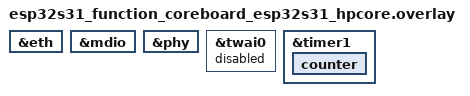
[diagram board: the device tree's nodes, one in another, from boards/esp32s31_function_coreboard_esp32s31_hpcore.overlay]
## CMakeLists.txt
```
# SPDX-License-Identifier: GPL-3.0-or-later

cmake_minimum_required(VERSION 3.20.0)

find_package(Zephyr REQUIRED HINTS $ENV{ZEPHYR_BASE})
project(esp_sdr_txstream_eth)

include(${CMAKE_CURRENT_LIST_DIR}/../../lib/esp_sdr/place.cmake)

set(txs_dir ${CMAKE_CURRENT_LIST_DIR}/../../lib/esp_sdr/src/txs)
# The cookie protocol of the control port and the header templates are stream_eth's, compiled from there.
set(eth_dir ${CMAKE_CURRENT_LIST_DIR}/../stream_eth/src)
target_sources(app PRIVATE src/main.c src/tx_boot.c src/tx_shell.c src/tx_stream.c src/tx_tone.c
  src/tx_net.c src/tx_sess.c ${eth_dir}/ctlproto.c ${eth_dir}/netframe.c
  ${txs_dir}/txs_flip.c ${txs_dir}/txs_jit.c ${txs_dir}/txs_credit.c
  ${txs_dir}/txs_wire.c ${txs_dir}/txs_expand.c)
target_sources_ifdef(CONFIG_APP_TXS_INJECT app PRIVATE src/tx_inject.c)
target_include_directories(app PRIVATE ${txs_dir} ${eth_dir})

# The PIE kernel: preprocessed by Zephyr's compiler (the placement macros), assembled by Espressif's
# assembler (xespv2p2), the rest by Zephyr's.
if(CONFIG_ESP_SDR_TXS_PIE)
  find_program(ESP_AS riscv32-esp-elf-as)
  if(NOT ESP_AS)
    message(FATAL_ERROR "CONFIG_ESP_SDR_TXS_PIE needs riscv32-esp-elf-as (the dev shell has it)")
  endif()
  set(pie_s ${CMAKE_CURRENT_BINARY_DIR}/txs_pie.s)
  set(pie_o ${CMAKE_CURRENT_BINARY_DIR}/txs_pie.o)
  add_custom_command(OUTPUT ${pie_o}
    COMMAND ${CMAKE_C_COMPILER} -E -P -x assembler-with-cpp -imacros ${AUTOCONF_H}
            -I${ZEPHYR_BINARY_DIR}/include/generated -I${CMAKE_CURRENT_LIST_DIR}/../../include
            -o ${pie_s} ${txs_dir}/txs_pie.S
    COMMAND ${ESP_AS} -march=rv32imafc_zicsr_zifencei_xespv2p2 -mabi=ilp32f -o ${pie_o} ${pie_s}
    DEPENDS ${txs_dir}/txs_pie.S ${ZEPHYR_BINARY_DIR}/include/generated/esp_sdr_place_rules.h
    VERBATIM)
  target_sources(app PRIVATE ${pie_o} ${txs_dir}/txs_pie.c)
  set_source_files_properties(${pie_o} PROPERTIES EXTERNAL_OBJECT TRUE GENERATED TRUE)
endif()
target_include_directories(app PRIVATE ${CMAKE_CURRENT_LIST_DIR}/../../include)

# net_buf_unref() and what it calls run on CPU 1, per packet: IRAM, not the flash cache
zephyr_linker_sources(RAMFUNC_SECTION ${CMAKE_CURRENT_LIST_DIR}/ram_netbuf.ld)

# The layout of the transmit image is checked after every link: PSRAM only where it is safe (a store fault at
# boot, or CPU 1 and the interrupts reaching it, otherwise), the rest of scripts/tcm_groups.py --tx. A failure
# fails the build.
if(CONFIG_ESP_SDR_S31_TXMEM)
  add_custom_target(txs_layout_check ALL
    COMMAND ${CMAKE_COMMAND} -E env READELF=${CMAKE_READELF} ${PYTHON_EXECUTABLE}
            ${CMAKE_CURRENT_LIST_DIR}/../../scripts/tcm_groups.py
            ${ZEPHYR_BINARY_DIR}/${CONFIG_KERNEL_BIN_NAME}.elf --tx
    VERBATIM)
  add_dependencies(txs_layout_check ${logical_target_for_zephyr_elf})
endif()
target_compile_options(app PRIVATE -O2)
```

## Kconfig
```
# SPDX-License-Identifier: GPL-3.0-or-later

mainmenu "ESP-SDR transmit stream over Ethernet"

config APP_TXS_INJECT
	bool "The injector: sample packets made on the board (tx tone, tx inject)"
	help
	  A thread on CPU 0 that makes the packets the sender would, for tests without a host. It costs
	  about 2.4 KB of group 3 (its stack, thread and ring) and a few hundred bytes of group 0, which
	  the network side leaves no room for: injector.conf builds it with two receive buffers less. With
	  it off (the default), the network is the only source and `tx tone` and `tx inject` answer "not
	  supported".

source "Kconfig.zephyr"
```

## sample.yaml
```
sample:
  name: ESP-SDR transmit stream over Ethernet
  description: >-
    The S31 DAC streamed by whole-group ownership flips on CPU 1, fed over UDP (control 4992, samples
    4994; vrt_tx), in the transmit memory layout, with the gigabit Ethernet up
common:
  tags: esp-sdr
  platform_allow:
    - esp32s31_function_coreboard/esp32s31/hpcore
  integration_platforms:
    - esp32s31_function_coreboard/esp32s31/hpcore
tests:
  sample.esp_sdr.txstream_eth:
    build_only: true
  sample.esp_sdr.txstream_eth.injector:
    build_only: true
    extra_args: EXTRA_CONF_FILE=injector.conf
```

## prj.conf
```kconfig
# The transmit stream: the DAC by two-group flips, a tone from the injector, Ethernet up.
# Memory layout and network buffers as apps/rxbench/txmem.conf.
CONFIG_ESP_SDR=y
CONFIG_ESP_SDR_PHY_ONLY=y
CONFIG_ESP_SDR_REPLAY=y
CONFIG_ESP_SDR_RX_DECIM=n
CONFIG_ESP_SDR_S31_TXMEM=y
CONFIG_ESP_SDR_TXS_PIE=y

CONFIG_LOG=y
CONFIG_LOG_MODE_DEFERRED=y
# 512 B: the buffer is in group 0 (BSS), where the IPI and per-CPU run queue code of PIN_ONLY and the PSRAM driver's
# code took the room
CONFIG_LOG_BUFFER_SIZE=512
# The main thread is the stream's control thread: chain on and off (PHY), the report
CONFIG_MAIN_STACK_SIZE=3072
CONFIG_PRINTK=y
CONFIG_SHELL=y
CONFIG_SHELL_STACK_SIZE=4096
# The injector runs at the lowest priority: the shell is one above it
CONFIG_SHELL_THREAD_PRIORITY_OVERRIDE=y
CONFIG_SHELL_THREAD_PRIORITY=13
# A stack overflow is caught at the next context switch (a word per thread)
CONFIG_STACK_SENTINEL=y
CONFIG_KERNEL_SHELL=y
CONFIG_THREAD_NAME=y
CONFIG_FPU_SHARING=y

# The deadman's timer
CONFIG_COUNTER=y

# PSRAM (16 MB octal on the CoreBoard) at 250 MHz, the MPLL at 500 MHz (esp_psram_impl_ap_oct.c sets the PLL for
# this speed; at 400 MHz, SPIRAM_SPEED_200M, the PLL-derived clocks would change). The stacks of the threads with
# slack and cold data go there, the rest stays in internal RAM: lib/esp_sdr/esp_sdr_txmem_s31.ld, place.h, README.
# main() logs the PLL-derived clocks once (tx_boot.c). CPU 1 never touches PSRAM.
CONFIG_ESP_SPIRAM=y
CONFIG_SPIRAM_MODE_OCT=y
CONFIG_SPIRAM_SPEED_250M=y

# Ethernet: YT8531 on RGMII, the fork's DWC MAC, gigabit.
CONFIG_NETWORKING=y
CONFIG_NET_L2_ETHERNET=y
CONFIG_ETH_DRIVER=y
CONFIG_ETHERNET_LOG_LEVEL_WRN=y
CONFIG_PHY_LOG_LEVEL_WRN=y
CONFIG_MDIO_LOG_LEVEL_WRN=y
CONFIG_MDIO=y
CONFIG_ETH_DWMAC_RX_FAST=y
CONFIG_ETH_DWMAC_TX_RAMFUNC=y
# the status and the replies go out as prepared frames (dwmac_send_frames), not through the stack
CONFIG_ETH_DWMAC_TX_FAST=y
CONFIG_NET_BUF_DATA_SIZE=1536
CONFIG_NET_BUF_ALIGNMENT=64
# 43 receive buffers of 1664 B in group 3: 16 with the MAC, TX_HOLD = 25 (src/tx_hold.h) for the stream, 2 for the
# stack (tx_stream.c checks). The stacks of the threads with slack in PSRAM (above) freed the room (9 buffers, 224 B
# left in group 3: the linker stops the build when a buffer more does not fit).
CONFIG_DWMAC_NB_RX_DESCS=16
CONFIG_NET_BUF_RX_COUNT=43
CONFIG_NET_PKT_RX_COUNT=16
CONFIG_NET_BUF_TX_COUNT=4
CONFIG_NET_PKT_TX_COUNT=4
CONFIG_DWMAC_NB_TX_DESCS=16

# DHCPv4, IPv6 link-local and autoconfiguration; answers ping and neighbour requests.
CONFIG_NET_IPV4=y
CONFIG_NET_IPV6=y
CONFIG_NET_UDP=y
CONFIG_NET_DHCPV4=y
CONFIG_NET_DHCPV4_INITIAL_DELAY_MAX=2
CONFIG_NET_IPV6_ND=y
CONFIG_NET_IF_UNICAST_IPV6_ADDR_COUNT=5
CONFIG_NET_IF_IPV6_PREFIX_COUNT=3
# The tables of the stack, sized for one host, one router and the DHCP server (group 0 has no room to spare: the PSRAM
# driver's code and data are in it)
CONFIG_NET_MAX_ROUTES=2
CONFIG_NET_IPV4_MAX_ROUTES=2
CONFIG_NET_IPV6_MAX_NEIGHBORS=4
CONFIG_NET_IPV4_MAX_NEIGHBORS=2
CONFIG_NET_MAX_CONN=5
CONFIG_NET_MAX_CONTEXTS=5
CONFIG_NET_CONFIG_SETTINGS=y
CONFIG_NET_CONFIG_NEED_IPV4=y
CONFIG_NET_CONFIG_NEED_IPV6=y
CONFIG_NET_CONFIG_MY_IPV4_ADDR=""
CONFIG_NET_CONFIG_PEER_IPV4_ADDR=""
CONFIG_NET_CONFIG_INIT_TIMEOUT=10
CONFIG_NET_SHELL=y
CONFIG_NET_STATISTICS=y
CONFIG_NET_STATISTICS_ETHERNET=y
CONFIG_NET_STATISTICS_ETHERNET_VENDOR=y

CONFIG_SYSTEM_WORKQUEUE_PRIORITY=7
CONFIG_NET_TC_THREAD_PREEMPTIVE=y
CONFIG_NET_TC_THREAD_PRIO_CUSTOM=y
CONFIG_NET_TC_TX_THREAD_BASE_PRIO=8
CONFIG_NET_TC_RX_THREAD_BASE_PRIO=8
CONFIG_NET_MGMT_EVENT_STACK_SIZE=3072
CONFIG_NET_RX_STACK_SIZE=4096
CONFIG_NET_TX_STACK_SIZE=4096
CONFIG_HEAP_MEM_POOL_SIZE=8192

# The network and every device interrupt on CPU 0, the stream's flips alone on CPU 1.
CONFIG_SMP=y
CONFIG_MP_MAX_NUM_CPUS=2
CONFIG_SCHED_CPU_MASK=y
# Every thread starts on CPU 0 alone (the network, the shell, the log, the status and control threads, main); the
# flip thread is pinned to CPU 1 before it starts (tx_stream.c). A wakeup then never sends CPU 1 a scheduler
# interrupt: with IPI_OPTIMIZE only the CPUs a thread may run on, and where it would preempt, are interrupted.
CONFIG_SCHED_CPU_MASK_PIN_ONLY=y
CONFIG_IPI_OPTIMIZE=y

# The status thread sleeps a tick at a time (src/tx_net.c): 100 us
CONFIG_SYS_CLOCK_TICKS_PER_SEC=10000
```

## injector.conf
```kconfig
# SPDX-License-Identifier: GPL-3.0-or-later
# The injector (tx tone, tx inject: sample packets made on the board, no host needed) next to the network
# side. Its 2.4 KB do not fit group 3 with the 43 receive buffers: two fewer (3.3 KB) make room. The
# injector holds TX_BUFFERS = 21 of the 41 and the MAC 16, which leaves 4 for the stack: for a bench without a
# host, not for the network run (op_start refuses a run from the network in this build).
#   west build ... -- -DEXTRA_CONF_FILE=injector.conf
CONFIG_APP_TXS_INJECT=y
CONFIG_NET_BUF_RX_COUNT=41
```

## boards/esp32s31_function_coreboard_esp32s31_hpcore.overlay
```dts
/*
 * SPDX-License-Identifier: GPL-3.0-or-later
 *
 * The gigabit Ethernet of the ESP32-S31-Function-CoreBoard-1: YT8531 on RGMII (GPIO4-19, MDC 5,
 * MDIO 6, PHY reset 7). TWAI shares GPIO13/14 with TX_CLK and RX_CLK. The diag16 pads (20-25,
 * 36-40, 42-44, 47, 48) are none of those.
 */

&eth {
	status = "okay";
};

&mdio {
	status = "okay";
};

&phy {
	status = "okay";
	/* Gigabit: the 125 MHz reference clock, so let the PHY offer 1000BASE-T. */
	/delete-property/ default-speeds;
};

&twai0 {
	status = "disabled";
};

/* The deadman of the DAC stream (src/tx_stream.c): a general purpose timer, interrupt on CPU 0. */
&timer1 {
	status = "okay";

	counter {
		status = "okay";
	};
};
```

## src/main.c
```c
/*
 * SPDX-License-Identifier: GPL-3.0-or-later
 *
 * The transmit stream's app: the shell commands "tx ..." in tx_shell.c, the network side in
 * tx_net.c (control on UDP 4992, samples through a hook on the MAC's receive path from UDP 4994), the
 * stream itself in tx_stream.c, the network as in apps/rxbench.
 */

#include <zephyr/app_version.h>
#include <zephyr/kernel.h>
#include <zephyr/drivers/ethernet/eth_dwmac_fast.h>
#include <zephyr/logging/log.h>
#include <zephyr/net/ethernet.h>
#include <zephyr/net/net_if.h>

#include "tx_boot.h"
#include "tx_net.h"
#include "tx_shell.h"
#include "tx_stream.h"

LOG_MODULE_REGISTER(txstream, LOG_LEVEL_INF);

int main(void)
{
	struct net_if *iface = net_if_get_first_by_type(&NET_L2_GET_NAME(ETHERNET));
	const struct device *eth;
	int ret;

	LOG_INF("txstream_eth %s", APP_VERSION_STRING);
	tx_mem_report();
	if (iface == NULL) {
		LOG_ERR("no Ethernet interface");
		tx_stream_ctl_run();
	}
	eth = net_if_get_device(iface);
	ret = tx_net_init(eth, iface);
	if (ret != 0) {
		LOG_ERR("network: %d", ret);
	}
	tx_shell_init(eth, iface);
	LOG_INF("\"tx boot\", then \"tx init\", then vrt_tx from the host (RF only after \"tx arm <minutes>\" with a subscriber)");
	/* this thread ends and starts the runs' chain and report (tx_stream.c) */
	tx_stream_ctl_run();
}
```

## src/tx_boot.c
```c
/*
 * SPDX-License-Identifier: GPL-3.0-or-later
 *
 * "tx boot": where the image, the heaps and the stacks ended up (the checks of scripts/tcm_groups.py
 * --tx, at run time), and the canary of the memory the DAC banks and the engine must not touch.
 */

#include <stdlib.h>
#include <string.h>

#include <zephyr/init.h>
#include <zephyr/kernel.h>
#include <zephyr/kernel_structs.h>
#include <zephyr/logging/log.h>
#include <soc/hp_system_reg.h>
#if defined(CONFIG_ESP_SPIRAM)
#include <esp_clk_tree.h>
#include <esp_psram.h>
#endif

#include <esp_sdr/esp_sdr.h>

#include "tx_boot.h"
#include "tx_stream.h"

LOG_MODULE_DECLARE(txstream, LOG_LEVEL_INF);

extern char _end[];
extern char _heap_sentry[];
extern char __esp_sdr_grp3_start[];
extern char __esp_sdr_grp3_end[];
#if defined(CONFIG_ESP_SDR_S31_TXMEM_PSRAM)
extern char __esp_sdr_psram_start[];
extern char __esp_sdr_psram_end[];
#endif
bool esp_sdr_s31_dump_ready(void);

#define GRP3_ORG 0x2F060000UL
#define GRP3_MAX 0x2F07AFB0UL
#define PSRAM_BASE 0x50000000UL
#define PSRAM_END  0x58000000UL
#define LPRAM_BASE 0x2E000000UL
#define LPRAM_END  0x2E008000UL
#define MAX_SHOWN 4U
#define MAX_THREADS 24U

static uint32_t seed;
static bool filled, with_stk;

static bool in_psram(uintptr_t a)
{
	return a >= PSRAM_BASE && a < PSRAM_END;
}

/* "group N", "psram" or "lp ram": where an address lies, for the reports */
static const char *where(uintptr_t a, char *buf, size_t n)
{
	if (in_psram(a)) {
		return "psram";
	}
	if (a >= LPRAM_BASE && a < LPRAM_END) {
		return "lp ram";
	}
	snprintk(buf, n, "group %u", GROUP_OF(a));
	return buf;
}

/* ---- PSRAM and the PLL-derived clocks ---- */

#if defined(CONFIG_ESP_SPIRAM)
/* The PSRAM's own init is a SYS_INIT at PRE_KERNEL_1 / CONFIG_KERNEL_INIT_PRIORITY_DEFAULT (soc/espressif/common/
 * esp_psram.c), the MSPI timing tuning and the chip's init included. These two bracket it by the CPU's cycle counter
 * (a 32 bit counter: 13 s at 320 MHz, enough; the kernel's clock is not up yet at PRE_KERNEL_1). */
static uint32_t psram_t0, psram_t1;

static uint32_t cycles(void)
{
	uint32_t v;

	__asm__ volatile("csrr %0, cycle" : "=r"(v));
	return v;
}

static uint32_t psram_us(void)
{
	return (psram_t1 - psram_t0) / (ESP_SDR_CPU_HZ / 1000000U);
}

static int psram_mark0(void)
{
	psram_t0 = cycles();
	return 0;
}

static int psram_mark1(void)
{
	psram_t1 = cycles();
	return 0;
}

/* literal priorities (the macro's section names do not take an expression) */
BUILD_ASSERT(CONFIG_KERNEL_INIT_PRIORITY_DEFAULT == 40, "tx_boot.c brackets the PSRAM init at priority 40");
SYS_INIT(psram_mark0, PRE_KERNEL_1, 39);
SYS_INIT(psram_mark1, PRE_KERNEL_1, 41);

static uint32_t clk_mhz(soc_module_clk_t c, uint32_t *hz_out)
{
	uint32_t hz = 0U;

	if (esp_clk_tree_src_get_freq_hz(c, ESP_CLK_TREE_SRC_FREQ_PRECISION_CACHED, &hz) != ESP_OK) {
		hz = 0U;
	}
	*hz_out = hz;
	return hz / 1000000U;
}

void tx_mem_report(void)
{
	uint32_t mpll, apll, f80, cpll;
	const uint32_t us = psram_us();

	(void)clk_mhz(SOC_MOD_CLK_MPLL, &mpll);
	(void)clk_mhz(SOC_MOD_CLK_APLL, &apll);
	(void)clk_mhz(SOC_MOD_CLK_PLL_F80M, &f80);
	(void)clk_mhz(SOC_MOD_CLK_CPLL, &cpll);
	/* short messages: the log buffer is 512 B, a long one is dropped whole */
	LOG_INF("PSRAM %s %uKB %dMHz init %uus", esp_psram_is_initialized() ? "up" : "NOT UP",
		(unsigned int)(esp_psram_get_size() / 1024U), CONFIG_SPIRAM_SPEED, us);
	LOG_INF("MPLL %u APLL(EMAC) %u", mpll, apll);
	LOG_INF("PLL_F80M(PTP) %u CPLL %u", f80, cpll);
	if (mpll != 500000000U || apll != 125000000U) {
		LOG_WRN("MPLL not 500 MHz or APLL not 125 MHz");
	}
#if defined(CONFIG_ESP_SDR_S31_TXMEM_PSRAM)
	LOG_INF("PSRAM %uB: stacks, net mgmt queue", (unsigned int)(__esp_sdr_psram_end - __esp_sdr_psram_start));
#endif
}

static void psram_print(const struct shell *sh)
{
	uint32_t mpll, apll, f80, cpll;

	(void)clk_mhz(SOC_MOD_CLK_MPLL, &mpll);
	(void)clk_mhz(SOC_MOD_CLK_APLL, &apll);
	(void)clk_mhz(SOC_MOD_CLK_PLL_F80M, &f80);
	(void)clk_mhz(SOC_MOD_CLK_CPLL, &cpll);
	shell_print(sh, "  PSRAM %s, %u KB at %d MHz, init %u us; MPLL %u Hz, EMAC ref (APLL) %u Hz, PLL_F80M %u Hz, "
		    "CPLL %u Hz", esp_psram_is_initialized() ? "up" : "NOT INITIALIZED",
		    (unsigned int)(esp_psram_get_size() / 1024U), CONFIG_SPIRAM_SPEED,
		    psram_us(), mpll, apll, f80, cpll);
}
#else
void tx_mem_report(void)
{
	LOG_INF("PSRAM: off");
}

static void psram_print(const struct shell *sh)
{
	shell_print(sh, "  PSRAM off");
}
#endif


static uint32_t pat(uintptr_t a)
{
	return (uint32_t)a * 0x9E3779B1U ^ seed;
}

static uintptr_t tail_start(void)
{
	return ROUND_UP((uintptr_t)__esp_sdr_grp3_end, 16U);
}

static void stack_range(uintptr_t *a, uintptr_t *e)
{
	size_t n;

	*a = (uintptr_t)tx_stream_stack(&n);
	*e = *a + n;
}

static void fill_range(uintptr_t a, uintptr_t e)
{
	for (; a < e; a += 4U) {
		*(volatile uint32_t *)a = pat(a);
	}
}

void tx_canary_fill(bool with_stack)
{
	uintptr_t sa, se;

	seed = k_cycle_get_32() | 1U;
	fill_range(TX_GROUP1, TX_GROUP1 + 2U * TCM_GROUP_SIZE);
	fill_range(tail_start(), GRP3_MAX);
	stack_range(&sa, &se);
	if (with_stack) {
		fill_range(sa, se);
	}
	with_stk = with_stack;
	filled = true;
}

static unsigned int check_range(const struct shell *sh, const char *name, uintptr_t a, uintptr_t e)
{
	unsigned int bad = 0U;

	for (uintptr_t p = a; p < e; p += 4U) {
		const uint32_t got = *(volatile uint32_t *)p;

		if (got != pat(p)) {
			if (bad++ < MAX_SHOWN) {
				shell_print(sh, "  %s 0x%08lx: 0x%08x, filled 0x%08x", name, (unsigned long)p,
					    got, pat(p));
			}
		}
	}
	return bad;
}

unsigned int tx_canary_check(const struct shell *sh)
{
	uintptr_t sa, se;
	unsigned int g1, g2, t3, stk = 0U;

	if (!filled) {
		shell_error(sh, "canary: not filled");
		return 1U;
	}
	g1 = check_range(sh, "group 1", TX_GROUP1, TX_GROUP2);
	g2 = check_range(sh, "group 2", TX_GROUP2, TX_GROUP2 + TCM_GROUP_SIZE);
	t3 = check_range(sh, "group 3 tail", tail_start(), GRP3_MAX);
	stack_range(&sa, &se);
	if (with_stk) {
		stk = check_range(sh, "stream stack", sa, se);
	}
	shell_print(sh, "canary: group 1 %u, group 2 %u, group 3 free tail %u (%u B), stream stack %s%u "
		    "words changed: %s", g1, g2, t3, (unsigned int)(GRP3_MAX - tail_start()),
		    with_stk ? "" : "not checked ", with_stk ? stk : 0U,
		    g1 + g2 + t3 + stk == 0U ? "PASS" : "FAIL");
	return g1 + g2 + t3 + stk;
}

static unsigned int fails;

static void check(const struct shell *sh, const char *what, bool ok)
{
	shell_print(sh, "  %-4s %s", ok ? "ok" : "FAIL", what);
	fails += ok ? 0U : 1U;
}

/* k_thread_foreach() runs its callback with the scheduler lock held: a shell_print() there is lost.
 * The stacks are collected unlocked and printed afterwards.
 */
struct thr_info {
	const char *name;
	uintptr_t start;
	size_t size;
};

struct thr_ctx {
	struct thr_info t[MAX_THREADS];
	unsigned int n, total;
};

static void thr_cb(const struct k_thread *t, void *user)
{
	struct thr_ctx *c = user;
	const char *name = k_thread_name_get((k_tid_t)t);

	if (c->total++ < MAX_THREADS) {
		c->t[c->n].name = name != NULL ? name : "?";
		c->t[c->n].start = t->stack_info.start;
		c->t[c->n].size = t->stack_info.size;
		c->n++;
	}
}

int tx_boot_report(const struct shell *sh)
{
	void *km = k_malloc(32), *lm = malloc(32);
	const uint32_t own = sys_read32(HP_SYSTEM_TCM_DATA_DUMP_CTRL_REG);
	const uintptr_t rx = tx_last_rx_buf();
	static struct thr_ctx ctx;

	fails = 0U;
	shell_print(sh, "tx boot: ownership register 0x%08x (7:0 group 0, 15:8 group 1, 23:16 group 2, "
		    "31:24 group 3), dump_ready %d", (unsigned int)own, esp_sdr_s31_dump_ready());
	shell_print(sh, "  image end %p (group %u), libc arena up to %p, group 3 noinit %p..%p (%u of %u B)",
		    _end, GROUP_OF(_end), _heap_sentry, __esp_sdr_grp3_start, __esp_sdr_grp3_end,
		    (unsigned int)(__esp_sdr_grp3_end - __esp_sdr_grp3_start),
		    (unsigned int)(GRP3_MAX - GRP3_ORG));
	shell_print(sh, "  k_malloc block %p (group %u), malloc block %p (group %u), last receive buffer "
		    "0x%08lx (group %u)", km, GROUP_OF(km), lm, GROUP_OF(lm), (unsigned long)rx,
		    GROUP_OF(rx));
	check(sh, "image ends below group 1", (uintptr_t)_end <= TX_GROUP1);
	check(sh, "libc arena ends below group 1", (uintptr_t)_heap_sentry <= TX_GROUP1);
	check(sh, "group 3 section starts at 0x2f060000", (uintptr_t)__esp_sdr_grp3_start == GRP3_ORG);
	check(sh, "group 3 section ends below the ROM boot stack", (uintptr_t)__esp_sdr_grp3_end <= GRP3_MAX);
	check(sh, "kernel heap block is in group 3", km != NULL && GROUP_OF(km) == 3U);
	check(sh, "libc heap block is in group 0", lm != NULL && GROUP_OF(lm) == 0U);
	if (rx != 0U) {
		check(sh, "receive buffers are in group 3", GROUP_OF(rx) == 3U);
	} else {
		shell_print(sh, "  --   no frame seen yet (send a ping, then tx boot again): receive buffer group unchecked");
	}
	k_free(km);
	free(lm);
	for (unsigned int i = 0; i < arch_num_cpus(); i++) {
		const uintptr_t is = (uintptr_t)_kernel.cpus[i].irq_stack;

		shell_print(sh, "  interrupt stack top cpu %u: %08lx (group %u)", i, (unsigned long)is,
			    GROUP_OF(is - 1U));
		check(sh, "interrupt stack is in group 3", GROUP_OF(is - 1U) == 3U);
	}
	ctx.n = ctx.total = 0U;
	k_thread_foreach_unlocked(thr_cb, &ctx);
	for (unsigned int i = 0; i < ctx.n; i++) {
		const uintptr_t a = ctx.t[i].start;

		char w[16];
		const char *n = ctx.t[i].name;
		/* what CPU 1 or the stream's timing runs on stays internal, and in no DAC bank */
		const bool internal = strcmp(n, "tx_flip") == 0 || strcmp(n, "tx_stat") == 0 ||
				      strncmp(n, "idle", 4) == 0;

		shell_print(sh, "  stack %-14s %08lx size %5u %s", n, (unsigned long)a, (unsigned int)ctx.t[i].size,
			    where(a, w, sizeof(w)));
		check(sh, "  thread stack is not in a DAC bank", in_psram(a) || (GROUP_OF(a) != 1U && GROUP_OF(a) != 2U));
		if (internal) {
			check(sh, "  the flip, status and idle threads' stacks are internal", !in_psram(a));
		}
	}
	check(sh, "all threads listed", ctx.total == ctx.n);
	/* the banks: group 1 and 2 hold nothing of the image (the engine owns them, or nothing does) */
	psram_print(sh);
	check(sh, "ownership register has no group 0 or group 3 bit (nothing there goes to the engine)",
	      (own & 0xff0000ffU) == 0U);
	tx_canary_fill(false);
	k_msleep(200);
	check(sh, "canary of groups 1 and 2 and the group 3 tail held for 200 ms", tx_canary_check(sh) == 0U);
	shell_print(sh, "tx boot: %s", fails == 0U ? "PASS" : "FAIL");
	return fails == 0U ? 0 : -EIO;
}
```

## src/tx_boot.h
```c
/*
 * SPDX-License-Identifier: GPL-3.0-or-later
 */

#ifndef TX_BOOT_H_
#define TX_BOOT_H_

#include <stdbool.h>
#include <stdint.h>

#include <zephyr/shell/shell.h>

#define TCM_BASE 0x2F000000UL
#define TCM_GROUP_SIZE 0x20000UL
#define TCM_GROUPS 4U
#define GROUP_OF(a) ((unsigned int)(((uintptr_t)(a) - TCM_BASE) / TCM_GROUP_SIZE))

/** The hook's view of a received frame, from tx_net.c: the buffer address of the last one. */
uintptr_t tx_last_rx_buf(void);

/** Canaries: groups 1 and 2 (the banks), the free tail of group 3 and the idle stream stack. */
void tx_canary_fill(bool with_stack);
/** Print what changed since tx_canary_fill(); returns the number of changed words. */
unsigned int tx_canary_check(const struct shell *sh);

/** Once after the init: PSRAM and the PLL-derived clocks (EMAC reference, PTP reference, MPLL) to the log. */
void tx_mem_report(void);

/** tx boot: addresses per group and run time layout checks; 0 when all pass. */
int tx_boot_report(const struct shell *sh);

#endif
```

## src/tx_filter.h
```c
/*
 * SPDX-License-Identifier: GPL-3.0-or-later
 *
 * The receive hook's filter (tx_net.c) as a pure function of a frame and the session: no Zephyr, no
 * state, so that the host test (tests/unit/txs/src/test_filter.c) feeds it frames. Header only; it is
 * inlined into the hook, which sits in IRAM.
 *
 * A frame for our MAC, IPv4 (no options, not a fragment) or IPv6 (UDP as the next header), UDP to the
 * sample port is the stream's: it either matches (the subscriber's address, port and the session's
 * stream ID) and is taken, or it is dropped for its reason. Anything else is the stack's.
 */

#ifndef TX_FILTER_H_
#define TX_FILTER_H_

#include <stdbool.h>
#include <stdint.h>
#include <string.h>

#define TXF_PORT 4994U

/** What the session knows; the control thread writes it while no run takes data. */
struct txf_state {
	bool v6;
	uint16_t sport;   /* the subscriber's port */
	uint8_t mac[6];   /* ours */
	uint8_t sid[4];   /* the stream ID as the packet has it (big endian) */
	uint8_t src[16];  /* the subscriber's address (4 bytes for IPv4) */
	uint8_t dst[16];  /* the address it sends to: ours */
};

enum txf_verdict {
	TXF_STACK,   /* not ours: the stack */
	TXF_LEN,     /* for the port, lengths inconsistent (drop) */
	TXF_IDLE,    /* for the port, no run takes data (drop) */
	TXF_SRC,     /* for the port, not from the subscriber's address and port (drop) */
	TXF_SID,     /* for the port, another stream ID (drop) */
	TXF_TAKE,    /* the stream's: the VITA packet is at *off, *len bytes */
};

static inline uint16_t txf_be16(const uint8_t *p)
{
	return (uint16_t)(((uint16_t)p[0] << 8) | p[1]);
}

/**
 * @param d the Ethernet frame from the destination address on, len bytes (no FCS)
 * @param accept a run takes data
 * @param off, @param vlen where the VITA packet starts in the frame and its length, for TXF_TAKE
 */
static inline enum txf_verdict txf_classify(const struct txf_state *s, bool accept, const uint8_t *d,
					    uint16_t len, uint16_t *off, uint16_t *vlen)
{
	unsigned int hdr, alen, sa;
	uint16_t ulen, iplen;
	bool v6;

	/* Ethernet 14, IPv4 20 or IPv6 40, UDP 8, a VITA header of 16 and a word */
	if (len < 14U + 20U + 8U + 20U || memcmp(d, s->mac, 6) != 0) {
		return TXF_STACK;
	}
	if (d[12] == 0x08U && d[13] == 0x00U) {
		/* IPv4: 5 words of header, UDP, no more fragments and a zero offset */
		if (d[14] != 0x45U || d[23] != 17U || ((d[20] & 0x3fU) | d[21]) != 0U) {
			return TXF_STACK;
		}
		v6 = false;
		hdr = 14U + 20U + 8U;
		alen = 4U;
		sa = 14U + 12U;
		iplen = (uint16_t)(txf_be16(d + 16) - 20U);
	} else if (d[12] == 0x86U && d[13] == 0xddU) {
		if (len < 14U + 40U + 8U + 20U || (d[14] & 0xf0U) != 0x60U || d[20] != 17U) {
			return TXF_STACK;
		}
		v6 = true;
		hdr = 14U + 40U + 8U;
		alen = 16U;
		sa = 14U + 8U;
		iplen = txf_be16(d + 18);
	} else {
		return TXF_STACK;
	}
	if (txf_be16(d + hdr - 6) != TXF_PORT) {
		return TXF_STACK;
	}
	/* for the sample port: from here on the frame is the stream's, taken or dropped */
	ulen = txf_be16(d + hdr - 4);
	if (ulen < 8U + 20U || ulen != iplen || hdr - 8U + ulen > len) {
		return TXF_LEN;
	}
	if (!accept) {
		return TXF_IDLE;
	}
	if (v6 != s->v6 || txf_be16(d + hdr - 8) != s->sport || memcmp(d + sa, s->src, alen) != 0 ||
	    memcmp(d + sa + alen, s->dst, alen) != 0) {
		return TXF_SRC;
	}
	if (memcmp(d + hdr + 4, s->sid, 4) != 0) {
		return TXF_SID;
	}
	*off = (uint16_t)hdr;
	*vlen = (uint16_t)(ulen - 8U);
	return TXF_TAKE;
}

#endif
```

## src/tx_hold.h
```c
/*
 * SPDX-License-Identifier: GPL-3.0-or-later
 *
 * Buffers of the receive pool the stream holds, one configuration for the board (the credit depth, the
 * hook's cap) and the host (the burst): plain C, no Zephyr.
 *
 * The board holds up to TX_HOLD buffers, in the ring and the thread's list together. What is in them at
 * the worst moment: the packets the credit lets the host send beyond the open window, which wait for the
 * next flip (TX_DEPTH_PKTS, the credit depth in packets), a burst the host puts on the wire back to back
 * (TX_BURST, which the board takes before it has placed the first of them), and two: one packet split by
 * the window's end and one being placed. So TX_DEPTH_PKTS = TX_HOLD - TX_BURST - 2, and the credit depth
 * the board reports (TXAK) is that many packets of the format. The pool has CONFIG_NET_BUF_RX_COUNT
 * buffers, the MAC takes CONFIG_DWMAC_NB_RX_DESCS of them, two stay for the stack (tx_stream.c checks).
 * More buffers (a bigger pool) make TX_HOLD larger and with it the depth. The pool is 43 buffers of 1664 B in TCM
 * group 3 (prj.conf; the stacks of the threads with slack are in PSRAM), so TX_HOLD = 43 - 16 - 2 = 25, a depth of
 * 19 packets (13338 words iq8, 6669 w32) where 16 buffers in a pool of 34 gave 10 (7020).
 */

#ifndef TX_HOLD_H_
#define TX_HOLD_H_

/* buffers the stream holds at most (tx_stream_put() refuses one more) */
#define TX_HOLD 25U
/* packets the host sends back to back at most (vrt_tx: TXP_BURST) */
#define TX_BURST 4U
/* packets of credit depth: the packets beyond the open window, as the TXAK's depth says in words */
#define TX_DEPTH_PKTS (TX_HOLD - TX_BURST - 2U)
/* the credit depth's buffers: depth = (TX_BUFFERS - 2) packets (txs_credit.h) */
#define TX_BUFFERS (TX_DEPTH_PKTS + 2U)

_Static_assert(TX_DEPTH_PKTS >= 2U, "the hold must leave room for a depth");
_Static_assert(TX_DEPTH_PKTS + TX_BURST + 2U <= TX_HOLD, "depth, burst and two must fit the hold");
/* the pool: the MAC's 16 descriptors, the hold and two for the stack are the 43 receive buffers of prj.conf
 * (tx_stream.c checks the pool against its config, this one the numbers the host's tools share) */
_Static_assert(TX_HOLD + 16U + 2U == 43U, "TX_HOLD, the MAC's descriptors and the stack's two are the pool of prj.conf");

#endif
```

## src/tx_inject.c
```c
/*
 * SPDX-License-Identifier: GPL-3.0-or-later
 *
 * The injector (tx_inject.h). The tone has a period of 351 samples and a packet is 351 or 702 of
 * them, so every packet that starts at a multiple of 351 carries the same payload: a ring of
 * TX_BUFFERS buffers of the receive pool is made once with the payload in them, and a packet is the
 * index and count patched into the 16 byte header and a reference taken. The stream's thread gives
 * the reference back when it is done (a buffer is free again at a reference count of 1), so nothing
 * is copied or allocated while it runs. It sends as far as the credit allows: the pace is the board's.
 * It spins (a thread of the lowest priority on CPU 0, below the shell, which prj.conf puts one above,
 * and the network). After a
 * stall or an underrun it jumps to the index the board asks to restart at (rounded up to 351).
 */

#include <string.h>

#include <zephyr/kernel.h>
#include <zephyr/net/net_pkt.h>
#include <zephyr/sys/atomic.h>
#include <zephyr/sys/barrier.h>

#include <esp_sdr/esp_sdr_place.h>

#include "tx_inject.h"
#include "tx_stream.h"
#include "tx_tone.h"
#include "txs_limits.h"

/* Ethernet 14, IPv4 20, UDP 8: the VITA packet then sits at 2 mod 4 in a frame that starts aligned */
#define HDR_BYTES 42U
#define MAX_BATCH 8U
#define SPIN_US   5U
#define STALL_SLICE_MS 10U /* a stall sleeps in slices, to see the stop request */

static struct tx_inj_cfg cfg;
static struct tx_inj_stats stats;
static atomic_t run;
static K_THREAD_STACK_DEFINE(inj_stack, 2048);
static struct k_thread inj_thread;
static atomic_t alive;
static struct net_buf *ring[TX_BUFFERS];
static struct txs_wire_cfg wc;
static uint32_t pkt_words;

void tx_inject_set(const struct tx_inj_cfg *c)
{
	cfg = *c;
	cfg.reorder = MIN(cfg.reorder, MAX_BATCH);
	cfg.stall_ms = MIN(cfg.stall_ms, TXS_STALL_MAX);
}

void tx_inject_get(struct tx_inj_cfg *c)
{
	*c = cfg;
}

void tx_inject_stats(struct tx_inj_stats *s)
{
	/* the injector is on this core: its 64 bit counters tear only if it preempts the copy */
	const unsigned int key = irq_lock();

	*s = stats;
	irq_unlock(key);
}

/* The ring: buffers with the payload of a packet at a multiple of 351, header patched per send. */
static int ring_make(enum txs_fmt fmt)
{
	const uint32_t bytes = TXS_WIRE_HDR_BYTES + pkt_words * (fmt == TXS_FMT_IQ8 ? 2U : 4U);

	for (uint32_t i = 0; i < TX_BUFFERS; i++) {
		ring[i] = net_pkt_get_reserve_rx_data(HDR_BYTES + bytes, K_NO_WAIT);
		if (ring[i] == NULL) {
			for (uint32_t k = 0; k < i; k++) {
				net_buf_unref(ring[k]);
				ring[k] = NULL;
			}
			return -ENOMEM;
		}
		net_buf_add(ring[i], HDR_BYTES + bytes);
		txs_wire_header(ring[i]->data + HDR_BYTES, &wc, 0, 0, pkt_words);
		tx_tone_pack(ring[i]->data + HDR_BYTES + TXS_WIRE_HDR_BYTES, 0, pkt_words, fmt);
	}
	return 0;
}

static void ring_free(void)
{
	for (uint32_t i = 0; i < TX_BUFFERS; i++) {
		if (ring[i] != NULL) {
			net_buf_unref(ring[i]);
			ring[i] = NULL;
		}
	}
}

static uint32_t ring_nfree(void)
{
	uint32_t n = 0U;

	for (uint32_t i = 0; i < TX_BUFFERS; i++) {
		n += __atomic_load_n(&ring[i]->ref, __ATOMIC_ACQUIRE) == 1U;
	}
	return n;
}

/* A free ring buffer (the stream is done with it), patched for the packet at idx; one reference more. */
static ESP_SDR_CODE(EVENT, inj_take) struct net_buf *inj_take(uint32_t *rr, uint64_t idx, uint8_t count)
{
	for (uint32_t i = 0; i < TX_BUFFERS; i++) {
		struct net_buf *b = ring[(*rr + i) % TX_BUFFERS];

		if (__atomic_load_n(&b->ref, __ATOMIC_ACQUIRE) == 1U) {
			*rr = (*rr + i + 1U) % TX_BUFFERS;
			txs_wire_header(b->data + HDR_BYTES, &wc, count, idx, pkt_words);
			b = net_buf_ref(b);
			return b;
		}
	}
	return NULL;
}

static uint32_t xorshift(uint32_t *s)
{
	*s ^= *s << 13;
	*s ^= *s >> 17;
	*s ^= *s << 5;
	return *s;
}

static uint64_t round_up(uint64_t x, uint32_t m)
{
	return (x + m - 1U) / m * m;
}

static void inj_entry(void *a, void *b, void *c)
{
	const uint32_t n = pkt_words;
	struct txs_status s;
	struct net_buf *bufs[MAX_BATCH];
	uint32_t rng = 0x1234567U, last_under = 0U, rr = 0U;
	uint64_t next = 0U;
	int64_t t_stall, t_start = k_uptime_get();
	uint8_t count = 0U;
	bool have = false;

	ARG_UNUSED(a);
	ARG_UNUSED(b);
	ARG_UNUSED(c);
	t_stall = t_start + 1000;
	while (atomic_get(&run) != 0) {
		const uint32_t batch = MAX(cfg.reorder, 1U);
		uint64_t first;

		if (!tx_stream_status(&s) || s.restart == 0U) {
			k_busy_wait(SPIN_US);
			continue;
		}
		stats.ms = (uint32_t)(k_uptime_get() - t_start);
		if (!have) {
			next = round_up(s.restart, TX_TONE_PERIOD);
			last_under = s.underruns;
			have = true;
		}
		if (cfg.stall_ms != 0U && k_uptime_get() >= t_stall) {
			uint32_t left = MIN(cfg.stall_ms, TXS_STALL_MAX);

			stats.stalls++;
			while (left != 0U && atomic_get(&run) != 0) {
				const uint32_t slice = MIN(left, STALL_SLICE_MS);

				k_msleep(slice);
				left -= slice;
			}
			t_stall = k_uptime_get() + 1000;
			continue;
		}
		/* behind the play position, or the board closed a window short: restart where it says */
		if (s.underruns != last_under || next + n <= s.play) {
			last_under = s.underruns;
			if (next < s.restart) {
				next = round_up(s.restart, TX_TONE_PERIOD);
				stats.align_words += next - s.restart;
				stats.resyncs++;
			}
		}
		if (next + (uint64_t)n * batch > s.credit) {
			stats.credit_waits++;
			k_busy_wait(SPIN_US);
			continue;
		}
		/* a whole batch needs its buffers: a packet never goes unsent for want of one */
		if (ring_nfree() < batch) {
			stats.no_buf++;
			k_busy_wait(SPIN_US);
			continue;
		}
		first = next;
		for (uint32_t i = 0; i < batch; i++) {
			const bool drop = cfg.loss_pm != 0U && xorshift(&rng) % 1000U < cfg.loss_pm;

			bufs[i] = NULL;
			if (drop) {
				stats.dropped++;
				continue;
			}
			bufs[i] = inj_take(&rr, first + (uint64_t)i * n, count++);
			if (bufs[i] != NULL) {
				tx_stream_inflight_add(1);
			}
		}
		next += (uint64_t)n * batch;
		stats.next = next;
		/* a batch goes out last packet first */
		for (uint32_t i = 0; i < batch; i++) {
			struct net_buf *x = bufs[batch - 1U - i];

			if (x == NULL) {
				continue;
			}
			if (tx_stream_put(x, HDR_BYTES, (uint16_t)(x->len - HDR_BYTES))) {
				stats.sent++;
				stats.words += n;
				stats.reordered += batch > 1U && i != batch - 1U - i;
			} else {
				stats.ring_full++;
				net_buf_unref(x);
				tx_stream_inflight_add(-1);
			}
		}
		if (batch == 1U && bufs[0] == NULL && !(cfg.loss_pm != 0U)) {
			k_busy_wait(SPIN_US);
		}
	}
	atomic_set(&alive, 0);
}

int tx_inject_start(void)
{
	const struct txs_wire_cfg *w = tx_stream_wire();
	k_tid_t t;
	int ret;

	if (atomic_get(&alive) != 0) {
		return -EBUSY;
	}
	memset(&stats, 0, sizeof(stats));
	wc = *w;
	pkt_words = w->max_words;
	ret = ring_make(w->fmt);
	if (ret != 0) {
		return ret;
	}
	atomic_set(&run, 1);
	atomic_set(&alive, 1);
	t = k_thread_create(&inj_thread, inj_stack, K_THREAD_STACK_SIZEOF(inj_stack), inj_entry, NULL, NULL,
			    NULL, K_LOWEST_APPLICATION_THREAD_PRIO, 0, K_FOREVER);
	k_thread_name_set(t, "tx_inject");
	ret = k_thread_cpu_pin(t, 0);
	if (ret != 0) {
		k_thread_abort(t);
		atomic_set(&alive, 0);
		ring_free();
		return ret;
	}
	k_thread_start(t);
	return 0;
}

bool tx_inject_stop(void)
{
	bool clean = true;

	atomic_set(&run, 0);
	if (atomic_get(&alive) != 0 && k_thread_join(&inj_thread, K_MSEC(200)) != 0) {
		/* it did not end (a stall is sliced, a send is short): end it, its buffers are not touched
		 * after this */
		k_thread_abort(&inj_thread);
		atomic_set(&alive, 0);
		stats.aborted++;
		clean = false;
	}
	/* what the stream still holds is unreferenced by it; ours go back to the pool at the last reference */
	ring_free();
	return clean;
}

/* How fast the packets can be made alone: patch, reference, give back, no stream and no credit. */
int tx_inject_bench(enum txs_fmt fmt, uint32_t ms, uint64_t *words_per_s, uint32_t *cyc_per_pkt)
{
	uint64_t n = 0U;
	uint32_t rr = 0U, c0, c1;
	int64_t t0, t1;

	if (tx_stream_active() || atomic_get(&alive) != 0) {
		return -EBUSY;
	}
	wc = (struct txs_wire_cfg){.stream_id = TX_STREAM_ID, .port = (uint16_t)TX_PORT, .fmt = fmt,
				   .max_words = fmt == TXS_FMT_IQ8 ? 702U : 351U};
	pkt_words = wc.max_words;
	if (ring_make(fmt) != 0) {
		return -ENOMEM;
	}
	t0 = k_uptime_get();
	__asm__ volatile("csrr %0, cycle" : "=r"(c0));
	do {
		for (uint32_t i = 0; i < 256U; i++) {
			struct net_buf *b = inj_take(&rr, (uint64_t)n * pkt_words, (uint8_t)n);

			if (b != NULL) {
				net_buf_unref(b);
				n++;
			}
		}
		t1 = k_uptime_get();
	} while (t1 - t0 < (int64_t)ms);
	__asm__ volatile("csrr %0, cycle" : "=r"(c1));
	ring_free();
	*words_per_s = n * pkt_words * 1000U / (uint64_t)MAX(t1 - t0, 1);
	*cyc_per_pkt = n != 0U ? (c1 - c0) / (uint32_t)MIN(n, 0xffffffffULL) : 0U;
	return 0;
}
```

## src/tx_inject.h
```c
/*
 * SPDX-License-Identifier: GPL-3.0-or-later
 *
 * The network's stand-in: a thread on CPU 0 that makes the packets the sender would,
 * 1420 B with absolute sample indexes (tx_tone.c's tone), in buffers of the receive pool, paced
 * by the credits the stream publishes, and hands them to tx_stream_put() as the receive hook will.
 * Optional loss, reorder and stall.
 */

#ifndef TX_INJECT_H_
#define TX_INJECT_H_

#include <stdbool.h>
#include <stdint.h>

#include "txs_wire.h"

struct tx_inj_cfg {
	/* packets dropped, in 1/1000 */
	uint32_t loss_pm;
	/* packets sent in reverse order, in batches of this many (0 or 1: in order) */
	uint32_t reorder;
	/* a pause of this many ms once a second (0: none, at most 50) */
	uint32_t stall_ms;
};

struct tx_inj_stats {
	uint64_t sent, words, dropped, reordered, stalls, resyncs, align_words, no_buf, ring_full, credit_waits, aborted;
	uint64_t next;
	uint32_t ms;
};

#if defined(CONFIG_APP_TXS_INJECT)
void tx_inject_set(const struct tx_inj_cfg *c);
void tx_inject_get(struct tx_inj_cfg *c);
/** Start the thread for the running stream's format. */
int tx_inject_start(void);
/** Ask it to end and wait for it (200 ms, then abort it); the ring goes back. Returns whether it ended
 * by itself. */
bool tx_inject_stop(void);
void tx_inject_stats(struct tx_inj_stats *s);
/** The packet rate alone: patch, reference, give back; no stream, no credit. cycles: per packet. */
int tx_inject_bench(enum txs_fmt fmt, uint32_t ms, uint64_t *words_per_s, uint32_t *cyc_per_pkt);
#else
/* Built without the injector (CONFIG_APP_TXS_INJECT=n): the network is the only source. */
#include <errno.h>
#include <string.h>

static inline void tx_inject_set(const struct tx_inj_cfg *c)
{
	(void)c;
}

static inline void tx_inject_get(struct tx_inj_cfg *c)
{
	memset(c, 0, sizeof(*c));
}

static inline int tx_inject_start(void)
{
	return -ENOTSUP;
}

static inline bool tx_inject_stop(void)
{
	return true;
}

static inline void tx_inject_stats(struct tx_inj_stats *s)
{
	memset(s, 0, sizeof(*s));
}

static inline int tx_inject_bench(enum txs_fmt fmt, uint32_t ms, uint64_t *words_per_s,
				  uint32_t *cyc_per_pkt)
{
	(void)fmt;
	(void)ms;
	(void)words_per_s;
	(void)cyc_per_pkt;
	return -ENOTSUP;
}
#endif

#endif
```

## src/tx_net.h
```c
/*
 * SPDX-License-Identifier: GPL-3.0-or-later
 *
 * The network side of the transmit stream (doc/dev/txs.md, "Network protocol"): the receive hook
 * that takes the sample packets of UDP port 4994, the control port 4992 on the stack (the cookie
 * protocol of apps/stream_eth plus TXGO, TXEN and TXPG), and the thread that sends TXST and TXPO.
 */

#ifndef TX_NET_H_
#define TX_NET_H_

#include <stdbool.h>
#include <stdint.h>

#include <zephyr/device.h>
#include <zephyr/net/net_if.h>
#include <zephyr/shell/shell.h>

/** UDP port of the control messages and the source port of the status. */
#define TX_CTL_PORT 4992U

/** Open the control port, start the control and status threads, take the receive hook. */
int tx_net_init(const struct device *eth, struct net_if *iface);

/** `tx arm <minutes>`: the subscriber there is now (-ENOENT without one) may ask for RF for that long; prints
 * its address, port and MAC. `tx disarm`. */
int tx_net_arm(const struct shell *sh, uint32_t minutes);
void tx_net_disarm(void);
/** Seconds of the arming left, 0: not armed. */
uint32_t tx_net_armed_s(void);

/** `tx net`. */
void tx_net_print(const struct shell *sh);

#endif
```

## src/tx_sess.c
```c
/*
 * SPDX-License-Identifier: GPL-3.0-or-later
 *
 * The control state machine of a network run: see tx_sess.h.
 */

#include <errno.h>
#include <string.h>

#include "tx_sess.h"

/* 1404 bytes of payload: 702 iq8 samples (a sample is one DAC word) or 351 ready words */
uint32_t tx_sess_max_words(uint8_t fmt)
{
	return fmt == TXP_FMT_IQ8 ? 702U : 351U;
}

uint32_t tx_sess_depth(const struct tx_sess *s, uint8_t fmt)
{
	return (s->buffers - 2U) * tx_sess_max_words(fmt);
}

void tx_sess_init(struct tx_sess *s, uint32_t buffers, uint32_t group)
{
	memset(s, 0, sizeof(*s));
	s->buffers = buffers;
	s->group = group;
}

void tx_sess_reset(struct tx_sess *s)
{
	s->running = false;
	s->have = false;
	s->nonce = 0U;
	memset(&s->ak, 0, sizeof(s->ak));
}

void tx_sess_ended(struct tx_sess *s)
{
	s->running = false;
}

void tx_sess_go(struct tx_sess *s, const struct tx_sess_ops *o, void *ctx, const struct txp_go *m,
		struct txp_ak *ak)
{
	enum txp_code code = txp_go_valid(m);
	const bool rf = (m->flags & TXP_GO_RF) != 0U;
	uint32_t id;
	int ret;

	memset(ak, 0, sizeof(*ak));
	ak->nonce = m->nonce;
	/* the PC resends until it hears: the same nonce gets the same answer while its run is alive; after
	 * the run ended it is a stale duplicate and starts nothing (code 7) */
	if (s->have && s->nonce == m->nonce) {
		if (s->running) {
			*ak = s->ak;
		} else {
			ak->code = TXP_NO_RESOURCE;
		}
		return;
	}
	if (code != TXP_OK) {
		ak->code = (uint16_t)code;
		return;
	}
	if (rf && !o->rf_ok(ctx, m->rate_msps)) {
		ak->code = TXP_RF_REFUSED;
		return;
	}
	if (s->running) {
		ak->code = TXP_BUSY;
		return;
	}
	do {
		id = o->rand32(ctx);
	} while (id == 0U);
	ret = o->start(ctx, m, id, rf);
	if (ret != 0) {
		ak->code = ret == -EBUSY ? TXP_BUSY : TXP_NO_RESOURCE;
		return;
	}
	ak->code = TXP_OK;
	ak->flags = rf ? TXP_AK_RF : 0U;
	ak->stream_id = id;
	ak->max_words = tx_sess_max_words(m->fmt);
	ak->depth = tx_sess_depth(s, m->fmt);
	ak->group = s->group;
	s->running = true;
	s->have = true;
	s->nonce = m->nonce;
	s->ak = *ak;
}

void tx_sess_en(struct tx_sess *s, const struct tx_sess_ops *o, void *ctx, const struct txp_en *m,
		struct txp_ak *ak)
{
	memset(ak, 0, sizeof(*ak));
	ak->nonce = m->nonce;
	ak->code = TXP_OK;
	if (s->running) {
		o->stop(ctx);
	}
}
```

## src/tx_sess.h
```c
/*
 * SPDX-License-Identifier: GPL-3.0-or-later
 *
 * The control state machine of a network run (doc/dev/txs.md, "Network protocol"): what a TXGO or a
 * TXEN from the subscriber does, and what the board answers. Plain C, no Zephyr calls: what the board
 * does (start the stream, stop it, the RF gate, the random number) comes in through the ops, so the
 * unit test (tests/unit/txs/src/test_sess.c) drives it on the host.
 */

#ifndef TX_SESS_H_
#define TX_SESS_H_

#include <stdbool.h>
#include <stdint.h>

#include "tx_proto.h"

struct tx_sess_ops {
	/** RF may go on air now: armed on the UART, `tx init` done, the tuned frequency passes txs_rf_ok(). */
	bool (*rf_ok)(void *ctx, uint8_t rate_msps);
	/** Start the stream; 0, or -errno (-EBUSY: a run goes on or has not been cleaned up). */
	int (*start)(void *ctx, const struct txp_go *go, uint32_t stream_id, bool rf);
	/** Drain and stop the run. */
	void (*stop)(void *ctx);
	/** A random 32 bit value. */
	uint32_t (*rand32)(void *ctx);
};

struct tx_sess {
	/** The packets the stream holds at most and the words of a window: the numbers TXAK carries. */
	uint32_t buffers, group;
	/** A run was started by the subscriber and the stream has not said it ended. */
	bool running;
	/** A run was started in this subscription (its TXAK is kept for a retried TXGO). */
	bool have;
	uint32_t nonce;
	struct txp_ak ak;
};

/** @param buffers the packets the stream holds at most, @param group words of a window */
void tx_sess_init(struct tx_sess *s, uint32_t buffers, uint32_t group);

/** The subscriber changed or went: forget the run (the caller stops it). */
void tx_sess_reset(struct tx_sess *s);

/** The stream reports the end of the run. */
void tx_sess_ended(struct tx_sess *s);

/** A TXGO from the subscriber (its cookie checked): the answer in *ak. */
void tx_sess_go(struct tx_sess *s, const struct tx_sess_ops *o, void *ctx, const struct txp_go *m,
		struct txp_ak *ak);

/** A TXEN from the subscriber: the answer in *ak (code 0, every other field 0, the nonce echoed). */
void tx_sess_en(struct tx_sess *s, const struct tx_sess_ops *o, void *ctx, const struct txp_en *m,
		struct txp_ak *ak);

/** Words in a data packet of the format, and the credit depth: (buffers - 2) of them. */
uint32_t tx_sess_max_words(uint8_t fmt);
uint32_t tx_sess_depth(const struct tx_sess *s, uint8_t fmt);

#endif
```
